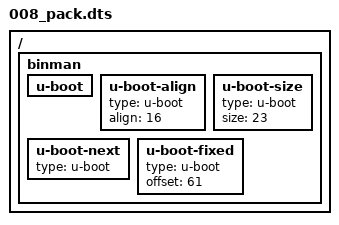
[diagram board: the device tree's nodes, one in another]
/dts-v1/;

/ {
	#address-cells = <1>;
	#size-cells = <1>;

	binman {
		u-boot {
		};

		u-boot-align {
			type = "u-boot";
			align = <16>;
		};

		u-boot-size {
			type = "u-boot";
			size = <23>;
		};

		u-boot-next {
			type = "u-boot";
		};

		u-boot-fixed {
			type = "u-boot";
			offset = <61>;
		};
	};
};
